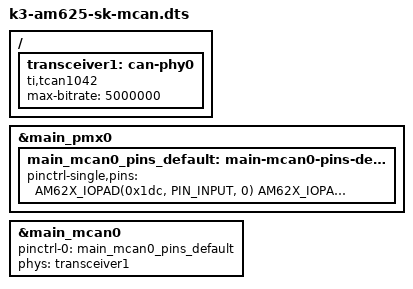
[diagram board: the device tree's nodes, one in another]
// SPDX-License-Identifier: GPL-2.0
/**
 * DT overlay for MCAN transceiver on AM625 SK
 *
 * Copyright (C) 2022 Texas Instruments Incorporated - https://www.ti.com/
 */

/dts-v1/;
/plugin/;
#include <dt-bindings/pinctrl/k3.h>

/ {
	fragment@101 {
		target-path = "/";

		__overlay__ {
			transceiver1: can-phy0 {
				compatible = "ti,tcan1042";
				#phy-cells = <0>;
				max-bitrate = <5000000>;
			};
		};
	};
};

&main_pmx0 {
	main_mcan0_pins_default: main-mcan0-pins-default {
		pinctrl-single,pins = <
			AM62X_IOPAD(0x1dc, PIN_INPUT, 0) /* (E15) MCAN0_RX */
			AM62X_IOPAD(0x1d8, PIN_OUTPUT, 0) /* (C15) MCAN0_TX */
		>;
	};
};

&main_mcan0 {
	status = "okay";
	pinctrl-names = "default";
	pinctrl-0 = <&main_mcan0_pins_default>;
	phys = <&transceiver1>;
};
